VERSION ""

NS_ :

BS_:

BU_: XXX

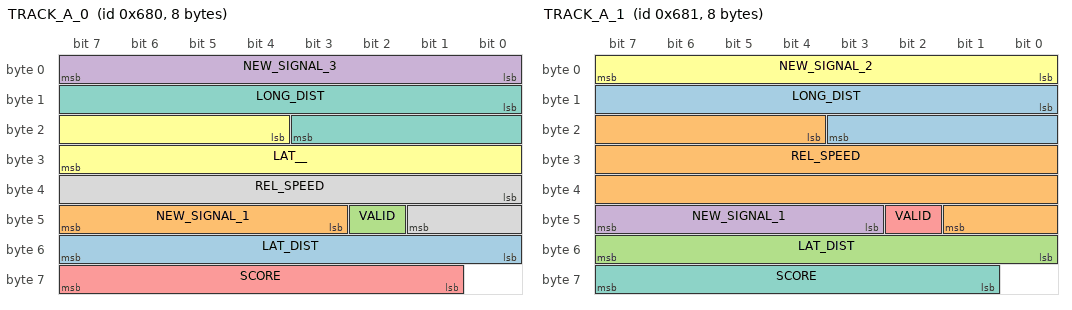
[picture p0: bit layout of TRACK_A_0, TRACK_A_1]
BO_ 1664 TRACK_A_0: 8 XXX
 SG_ LAT_DIST : 48|8@1+ (1,-128) [0|3] "" XXX
 SG_ NEW_SIGNAL_1 : 47|5@0+ (1,0) [0|63] "" XXX
 SG_ VALID : 42|1@1+ (1,0) [0|3] "" XXX
 SG_ NEW_SIGNAL_3 : 0|8@1+ (1,0) [0|15] "" XXX
 SG_ SCORE : 57|7@1+ (1,0) [0|3] "" XXX
 SG_ LAT__ : 20|12@1+ (0.047,-96) [0|7] "" XXX
 SG_ LONG_DIST : 8|12@1+ (0.1,0) [0|127] "" XXX
 SG_ REL_SPEED : 32|10@1+ (1,-512) [0|65535] "" XXX

BO_ 1665 TRACK_A_1: 8 XXX
 SG_ LONG_DIST : 8|12@1+ (1,0) [0|127] "" XXX
 SG_ REL_SPEED : 20|22@1+ (1,0) [0|65535] "" XXX
 SG_ LAT_DIST : 48|8@1+ (1,-128) [0|3] "" XXX
 SG_ NEW_SIGNAL_1 : 47|5@0+ (1,0) [0|63] "" XXX
 SG_ VALID : 42|1@1+ (1,0) [0|3] "" XXX
 SG_ NEW_SIGNAL_2 : 0|8@1+ (1,0) [0|255] "" XXX
 SG_ SCORE : 57|7@1+ (1,0) [0|3] "" XXX

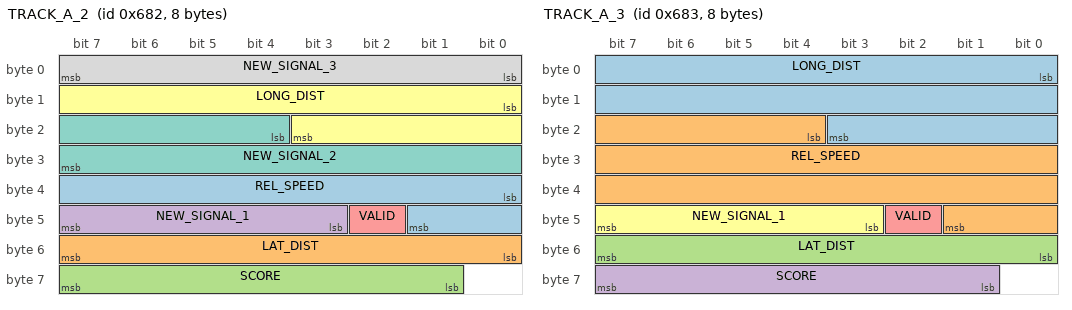
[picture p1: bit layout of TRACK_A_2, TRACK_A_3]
BO_ 1666 TRACK_A_2: 8 XXX
 SG_ REL_SPEED : 32|10@1+ (1,0) [0|65535] "" XXX
 SG_ LAT_DIST : 48|8@1+ (1,-128) [0|3] "" XXX
 SG_ SCORE : 57|7@1+ (1,0) [0|3] "" XXX
 SG_ NEW_SIGNAL_1 : 47|5@0+ (1,0) [0|63] "" XXX
 SG_ VALID : 42|1@1+ (1,0) [0|3] "" XXX
 SG_ LONG_DIST : 8|12@1+ (1,0) [0|127] "" XXX
 SG_ NEW_SIGNAL_2 : 20|12@1+ (1,0) [0|8191] "" XXX
 SG_ NEW_SIGNAL_3 : 0|8@1+ (1,0) [0|63] "" XXX

BO_ 1667 TRACK_A_3: 8 XXX
 SG_ LONG_DIST : 0|20@1+ (1,0) [0|127] "" XXX
 SG_ REL_SPEED : 20|22@1+ (1,0) [0|65535] "" XXX
 SG_ LAT_DIST : 48|8@1+ (1,-128) [0|3] "" XXX
 SG_ SCORE : 57|7@1+ (1,0) [0|3] "" XXX
 SG_ VALID : 42|1@1+ (1,0) [0|3] "" XXX
 SG_ NEW_SIGNAL_1 : 47|5@0+ (1,0) [0|63] "" XXX

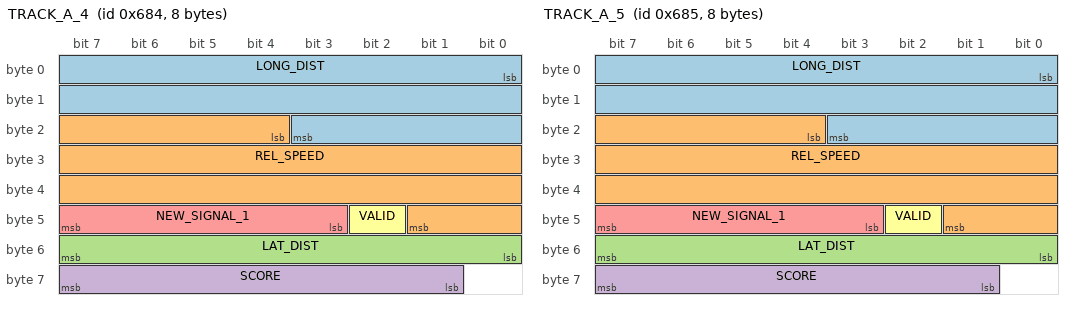
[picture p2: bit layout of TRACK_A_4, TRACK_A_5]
BO_ 1668 TRACK_A_4: 8 XXX
 SG_ LONG_DIST : 0|20@1+ (1,0) [0|127] "" XXX
 SG_ REL_SPEED : 20|22@1+ (1,0) [0|65535] "" XXX
 SG_ LAT_DIST : 48|8@1+ (1,-128) [0|3] "" XXX
 SG_ SCORE : 57|7@1+ (1,0) [0|3] "" XXX
 SG_ NEW_SIGNAL_1 : 47|5@0+ (1,0) [0|63] "" XXX
 SG_ VALID : 42|1@1+ (1,0) [0|3] "" XXX

BO_ 1669 TRACK_A_5: 8 XXX
 SG_ LONG_DIST : 0|20@1+ (1,0) [0|127] "" XXX
 SG_ REL_SPEED : 20|22@1+ (1,0) [0|65535] "" XXX
 SG_ LAT_DIST : 48|8@1+ (1,-128) [0|3] "" XXX
 SG_ SCORE : 57|7@1+ (1,0) [0|3] "" XXX
 SG_ NEW_SIGNAL_1 : 47|5@0+ (1,0) [0|63] "" XXX
 SG_ VALID : 42|1@1+ (1,0) [0|3] "" XXX

CM_ SG_ 1664 SCORE "127 = confident, 87 = low confidence, 0 = no tracking";
